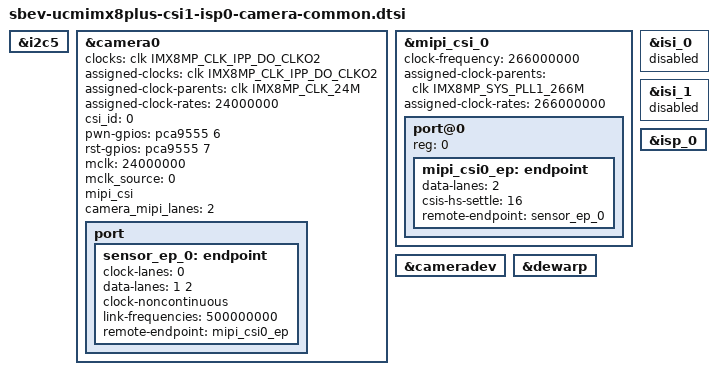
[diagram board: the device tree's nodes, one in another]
// SPDX-License-Identifier: GPL-2.0-only OR MIT

&i2c5 {
	status = "okay";
};

&camera0 {
	clocks = <&clk IMX8MP_CLK_IPP_DO_CLKO2>;
	clock-names = "xclk";
	assigned-clocks = <&clk IMX8MP_CLK_IPP_DO_CLKO2>;
	assigned-clock-parents = <&clk IMX8MP_CLK_24M>;
	assigned-clock-rates = <24000000>;
	csi_id = <0>;
	pwn-gpios = <&pca9555 6 GPIO_ACTIVE_HIGH>;
	rst-gpios = <&pca9555 7 GPIO_ACTIVE_HIGH>;
	mclk = <24000000>;
	mclk_source = <0>;
	mipi_csi;
	camera_mipi_lanes = <2>;
	status = "okay";

	port {
		sensor_ep_0: endpoint {
			clock-lanes = <0>;
			data-lanes = <1 2>;
			clock-noncontinuous;
			link-frequencies = /bits/ 64 <500000000>;
			remote-endpoint = <&mipi_csi0_ep>;
		};
	};
};

&mipi_csi_0 {
	#address-cells = <1>;
	#size-cells = <0>;
	clock-frequency = <266000000>;
	assigned-clock-parents = <&clk IMX8MP_SYS_PLL1_266M>;
	assigned-clock-rates = <266000000>;
	status = "okay";

	port@0 {
		reg = <0>;
		mipi_csi0_ep: endpoint {
			data-lanes = <2>;
			csis-hs-settle = <16>;
			remote-endpoint = <&sensor_ep_0>;
		};
	};
};

&cameradev {
	status = "okay";
};

&isi_0 {
	status = "disabled";
};

&isi_1 {
	status = "disabled";
};

&isp_0 {
	status = "okay";
};

&dewarp {
	status = "okay";
};
